# HC32K118 register map
File version: 1.0
CPU: CM0+ r0p1, little endian, no MPU, no FPU, 2 interrupt priority bits
Registers are 32-bit, read-write, reset 0x0 unless marked. A register's access mark holds for its fields unless they carry their own. Offsets are from the block's base; lines under a group give offsets from that group; [hi:lo] are bit positions; {n}, {i} and the like mark numbered series; 'fields as' and 'values as' point back to an identical list; <NAME> marks a mode.

## Memory map
0x01000A00 ICGA size 0x4C
0x40000000 CTC size 0xE
0x40000400 EFM size 0x687
0x40000C00 AOS size 0x174
0x40001800 USART1 size 0x1C — desc USART
0x40001C00 USART2 size 0x1C — desc USART
0x40002000 USART3 size 0x20 — desc USART
0x40002400 USART4 size 0x20 — desc USART
0x40003800 SPI1 size 0x1C — desc SPI
0x40003C00 SPI2 size 0x1C — desc SPI
0x40004800 I2C size 0x34
0x40005400 FCM size 0x24
0x40005800 TMR0 size 0x18
0x40005C00 TMR21 size 0x24 — desc TMR2
0x40006000 TMR22 size 0x24 — desc TMR2
0x40006800 TMR4 size 0xEA
0x40006C00 EMB size 0x1C
0x40007000 TMRA size 0x15E
0x4000B800 ADC size 0xB1
0x4000C800 CMP size 0x16
0x4000CC00 SWDT size 0xC
0x4000D400 RTC size 0x61
0x40010C00 SRAMC size 0x24
0x40011000 INTC size 0x90
0x40011400 MCAN size 0xFC
0x40013000 DMA size 0x110
0x40013400 PERIC size 0x4
0x40013800 GPIO size 0x70E
0x40014000 PWC size 0x41
0x40014100 RMU size 0x2
0x40014400 CMU size 0x41
0x40015000 DBGC size 0x8
0x40015400 CRC size 0x100
0x40017800 ICGB size 0x1F
0xE0042000 DBGC_T size 0x20

## ADC
Base 0x4000B800
0x00 STR 8-bit
  [0] STRT
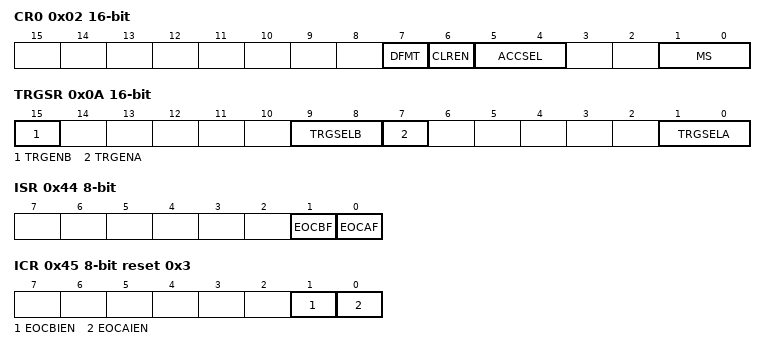
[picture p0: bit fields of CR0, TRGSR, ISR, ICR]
0x02 CR0 16-bit
  [7] DFMT, [6] CLREN, [5:4] ACCSEL, [1:0] MS
0x04 CR1 16-bit
  [2] RSCHSEL
0x0A TRGSR 16-bit
  [15] TRGENB, [9:8] TRGSELB, [7] TRGENA, [1:0] TRGSELA
0x0C CHSELRA 16-bit
  [13:0] CHSELA
0x10 CHSELRB 16-bit
  [13:0] CHSELB
0x18 EXCHSELR 8-bit
  [0] EXCHSEL
0x20 SSTR 8-bit reset 0xB
0x44 ISR 8-bit ro
  [1] EOCBF, [0] EOCAF
0x45 ICR 8-bit reset 0x3
  [1] EOCBIEN, [0] EOCAIEN
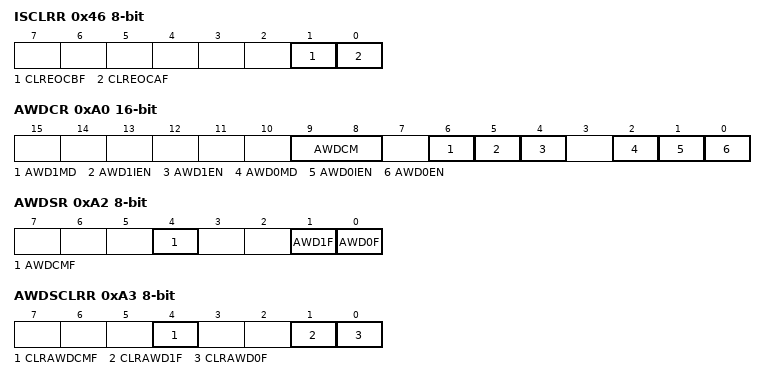
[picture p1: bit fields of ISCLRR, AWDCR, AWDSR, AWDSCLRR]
0x46 ISCLRR 8-bit wo
  [1] CLREOCBF, [0] CLREOCAF
{0x50+2i} DR{i} 16-bit ro (i=0..13)
0xA0 AWDCR 16-bit
  [9:8] AWDCM, [6] AWD1MD, [5] AWD1IEN, [4] AWD1EN, [2] AWD0MD, [1] AWD0IEN, [0] AWD0EN
0xA2 AWDSR 8-bit ro
  [4] AWDCMF, [1] AWD1F, [0] AWD0F
0xA3 AWDSCLRR 8-bit wo
  [4] CLRAWDCMF, [1] CLRAWD1F, [0] CLRAWD0F
0xA4 AWD0DR0 16-bit
0xA6 AWD0DR1 16-bit reset 0xFFFF
0xA8 AWD0CHSR 8-bit
  [4:0] AWDCH
0xAC AWD1DR0 16-bit
0xAE AWD1DR1 16-bit reset 0xFFFF
0xB0 AWD1CHSR 8-bit
  [4:0] AWDCH

## AOS
Base 0x40000C00
0x00 INTSFTTRG wo
  [0] STRG
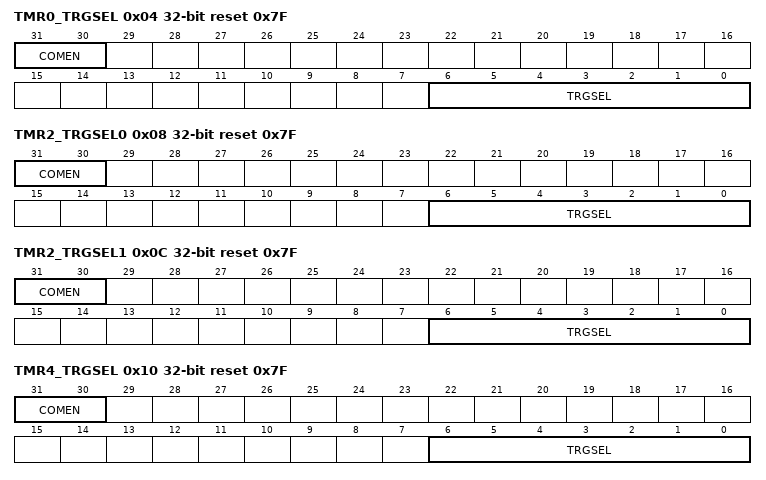
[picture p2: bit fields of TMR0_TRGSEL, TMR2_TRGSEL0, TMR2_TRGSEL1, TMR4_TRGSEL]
0x04 TMR0_TRGSEL reset 0x7F
  [31:30] COMEN, [6:0] TRGSEL
0x08 TMR2_TRGSEL0 reset 0x7F
  [31:30] COMEN, [6:0] TRGSEL
0x0C TMR2_TRGSEL1 reset 0x7F
  [31:30] COMEN, [6:0] TRGSEL
0x10 TMR4_TRGSEL reset 0x7F
  [31:30] COMEN, [6:0] TRGSEL
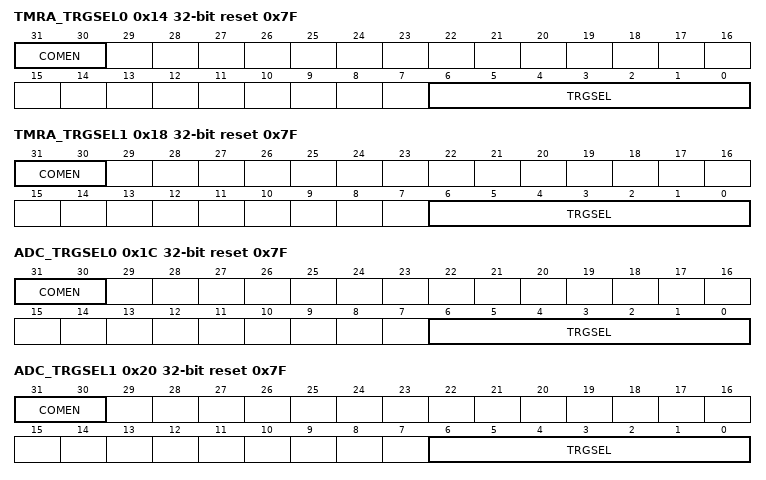
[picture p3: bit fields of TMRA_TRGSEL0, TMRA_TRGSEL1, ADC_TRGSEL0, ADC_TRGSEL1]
0x14 TMRA_TRGSEL0 reset 0x7F
  [31:30] COMEN, [6:0] TRGSEL
0x18 TMRA_TRGSEL1 reset 0x7F
  [31:30] COMEN, [6:0] TRGSEL
0x1C ADC_TRGSEL0 reset 0x7F
  [31:30] COMEN, [6:0] TRGSEL
0x20 ADC_TRGSEL1 reset 0x7F
  [31:30] COMEN, [6:0] TRGSEL
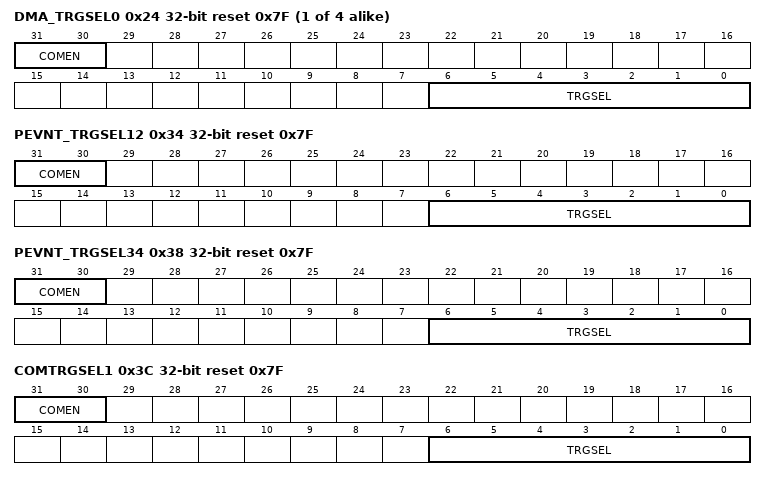
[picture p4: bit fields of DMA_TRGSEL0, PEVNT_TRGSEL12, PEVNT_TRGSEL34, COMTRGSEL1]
{0x24+4i} DMA_TRGSEL{i} reset 0x7F (i=0..3)
  [31:30] COMEN, [6:0] TRGSEL
0x34 PEVNT_TRGSEL12 reset 0x7F
  [31:30] COMEN, [6:0] TRGSEL
0x38 PEVNT_TRGSEL34 reset 0x7F
  [31:30] COMEN, [6:0] TRGSEL
0x3C COMTRGSEL1 reset 0x7F
  [31:30] COMEN, [6:0] TRGSEL
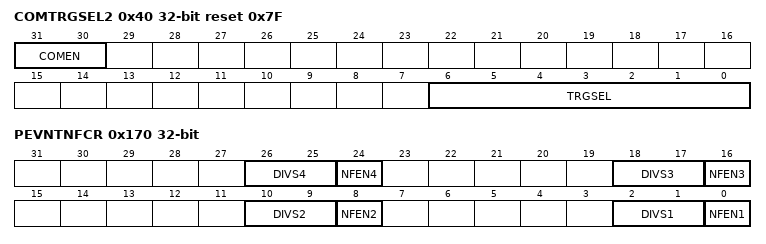
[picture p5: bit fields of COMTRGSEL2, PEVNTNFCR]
0x40 COMTRGSEL2 reset 0x7F
  [31:30] COMEN, [6:0] TRGSEL
{0xE4+0x1C*i} PEVNTDIRR{i} (i=1..4)
  [15:0] PDIR
{0xE8+0x1C*i} PEVNTIDR{i} ro (i=1..4)
  [15:0] PIN
{0xEC+0x1C*i} PEVNTODR{i} (i=1..4)
  [15:0] POUT
{0xF0+0x1C*i} PEVNTORR{i} (i=1..4)
  [15:0] POR
{0xF4+0x1C*i} PEVNTOSR{i} (i=1..4)
  [15:0] POS
{0xF8+0x1C*i} PEVNTRISR{i} (i=1..4)
  [15:0] RIS
{0xFC+0x1C*i} PEVNTFALR{i} (i=1..4)
  [15:0] FAL
0x170 PEVNTNFCR
  [8n-6:8n-7] DIVS{n} (n=1..4), [8n-8] NFEN{n} (n=1..4)

## CMP
Base 0x4000C800
0x00 MDR 8-bit
  [0] CENA
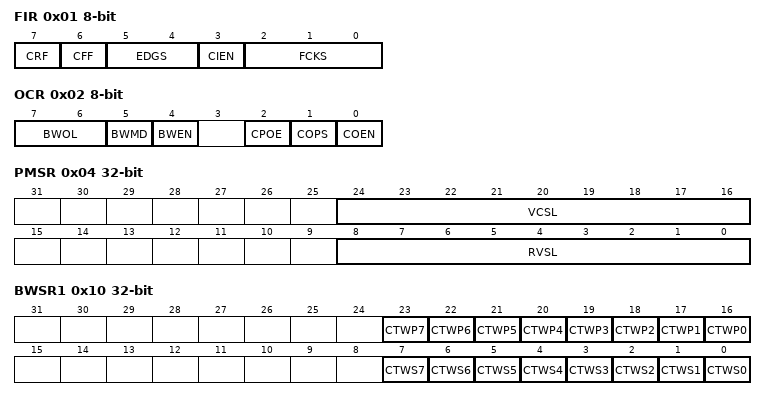
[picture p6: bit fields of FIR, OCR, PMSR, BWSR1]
0x01 FIR 8-bit
  [7] CRF, [6] CFF, [5:4] EDGS, [3] CIEN, [2:0] FCKS
0x02 OCR 8-bit
  [7:6] BWOL, [5] BWMD, [4] BWEN, [2] CPOE, [1] COPS, [0] COEN
0x03 OMR 8-bit ro
  [0] CMON
0x04 PMSR
  [24:16] VCSL, [8:0] RVSL
0x0C DADR 16-bit
  [7:0] DATA
0x0E DACR 16-bit
  [0] DAE
0x10 BWSR1
  [n+16] CTWP{n} (n=0..7), [n] CTWS{n} (n=0..7)
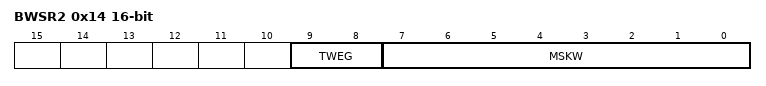
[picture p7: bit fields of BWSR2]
0x14 BWSR2 16-bit
  [9:8] TWEG, [7:0] MSKW
